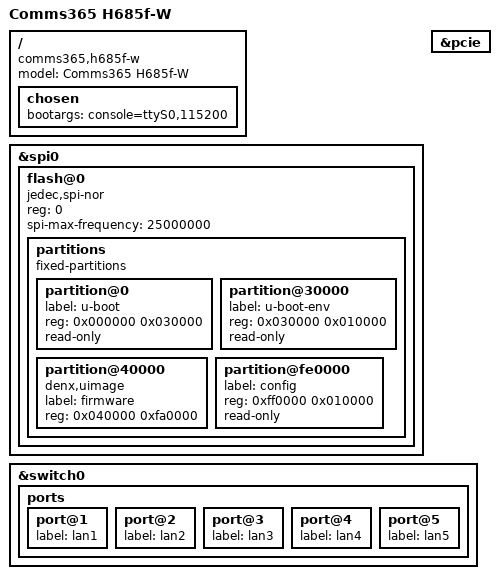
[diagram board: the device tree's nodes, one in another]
// SPDX-License-Identifier: GPL-2.0-or-later OR MIT

#include "mt7621.dtsi"

#include <dt-bindings/gpio/gpio.h>
#include <dt-bindings/input/input.h>
#include <dt-bindings/leds/common.h>

/ {
	compatible = "comms365,h685f-w", "H685-MT7621", "mediatek,mt7621-soc";
	model = "Comms365 H685f-W";

	chosen {
		bootargs = "console=ttyS0,115200";
	};
};

&spi0 {
	status = "okay";

	flash@0 {
		compatible = "jedec,spi-nor";
		reg = <0>;
		spi-max-frequency = <25000000>;

		partitions {
			compatible = "fixed-partitions";
			#address-cells = <1>;
			#size-cells = <1>;

			partition@0 {
				label = "u-boot";
				reg = <0x000000 0x030000>;
				read-only;
			};

			partition@30000 {
				label = "u-boot-env";
				reg = <0x030000 0x010000>;
				read-only;
			};

			partition@40000 {
				compatible = "denx,uimage";
				label = "firmware";
				reg = <0x040000 0xfa0000>;
			};

			partition@fe0000 {
				label = "config";
				reg = <0xff0000 0x010000>;
				read-only;
			};
		};
	};
};

&pcie {
	status = "okay";
};

&switch0 {
	ports {
		port@1 {
			status = "okay";
			label = "lan1";
		};

		port@2 {
			status = "okay";
			label = "lan2";
		};

		port@3 {
			status = "okay";
			label = "lan3";
		};
		port@4 {
			status = "okay";
			label = "lan4";
		};
		port@5 {
			status = "okay";
			label = "lan5";
		};
	};
};
